# nrf9120_MLM1 register map
Vendor: Nordic Semiconductor; Series: nrf91; File version: 1
CPU: CM4 r0p1, little endian, MPU, FPU, 3 interrupt priority bits
Registers are 32-bit, read-write, reset 0x0 unless marked. A register's access mark holds for its fields unless they carry their own. Offsets are from the block's base; [hi:lo] are bit positions; lines under a group give offsets from that group; {n}, {i} and the like mark numbered series; 'fields as' and 'values as' point back to an identical list.

## SAADC — Analog to Digital Converter
Base 0x4000B000
0x00 TASKS_START wo — Start the ADC and prepare the result buffer in RAM
0x04 TASKS_SAMPLE wo — Take one ADC sample, if scan is enabled all channels are sampled
0x08 TASKS_STOP wo — Stop the ADC and terminate any on-going conversion
0x0C TASKS_CALIBRATEOFFSET wo — Starts offset auto-calibration
0x10 TASKS_CALIBRATEGAIN wo — Starts gain auto-calibration
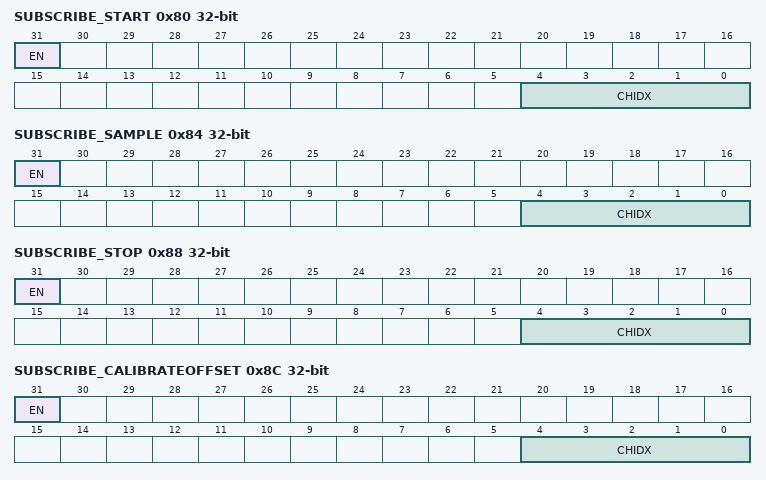
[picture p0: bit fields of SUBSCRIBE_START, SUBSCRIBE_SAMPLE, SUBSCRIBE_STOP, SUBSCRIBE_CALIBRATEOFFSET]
0x80 SUBSCRIBE_START — Subscribe configuration for TASKS_START
  [31] EN
    0=Disabled (Disable subscription); 1=Enabled (Enable subscription)
  [4:0] CHIDX — Channel the TASKS_START will subscribe to.
0x84 SUBSCRIBE_SAMPLE — Subscribe configuration for TASKS_SAMPLE
  [31] EN
    values as SUBSCRIBE_START.EN
  [4:0] CHIDX — Channel the TASKS_SAMPLE will subscribe to.
0x88 SUBSCRIBE_STOP — Subscribe configuration for TASKS_STOP
  [31] EN
    values as SUBSCRIBE_START.EN
  [4:0] CHIDX — Channel the TASKS_STOP will subscribe to.
0x8C SUBSCRIBE_CALIBRATEOFFSET — Subscribe configuration for TASKS_CALIBRATEOFFSET
  [31] EN
    values as SUBSCRIBE_START.EN
  [4:0] CHIDX — Channel the TASKS_CALIBRATEOFFSET will subscribe to.
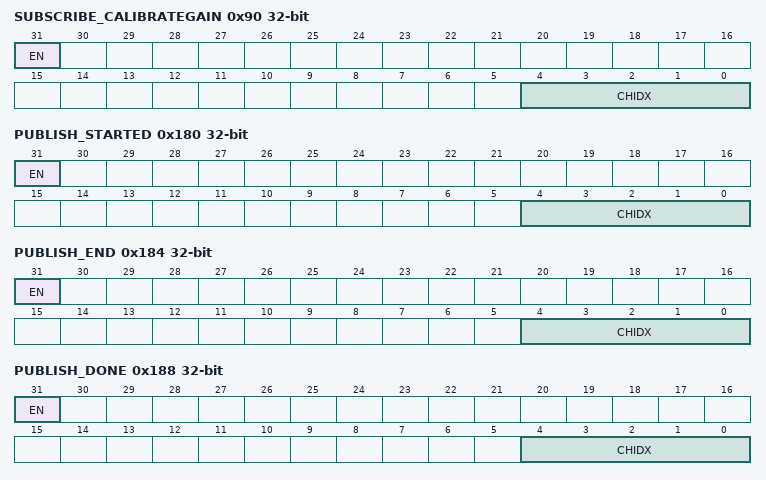
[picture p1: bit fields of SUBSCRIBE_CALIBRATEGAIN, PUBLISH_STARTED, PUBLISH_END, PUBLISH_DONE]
0x90 SUBSCRIBE_CALIBRATEGAIN — Subscribe configuration for TASKS_CALIBRATEGAIN
  [31] EN
    values as SUBSCRIBE_START.EN
  [4:0] CHIDX — Channel the TASKS_CALIBRATEGAIN will subscribe to.
0x100 EVENTS_STARTED — The ADC has started
0x104 EVENTS_END — The ADC has filled up the Result buffer
0x108 EVENTS_DONE — A conversion task has been completed. Depending on the mode, multiple conversions might be needed for a result to be transferred to RAM.
0x10C EVENTS_RESULTDONE — A result is ready to get transferred to RAM. Result is available in REGRESULT register
0x110 EVENTS_CALIBRATEDONE — Calibration is complete
0x114 EVENTS_STOPPED — The ADC has stopped
{0x118+8i} EVENTS_CH[{i}] (i=0..7) group — Unspecified
  0x00 LIMITH — Description cluster[0]: Last results is equal or above CH[0].LIMIT.HIGH
  0x04 LIMITL — Description cluster[0]: Last results is equal or below CH[0].LIMIT.LOW
0x180 PUBLISH_STARTED — Publish configuration for EVENTS_STARTED
  [31] EN
    0=Disabled (Disable publishing); 1=Enabled (Enable publishing)
  [4:0] CHIDX — Channel the EVENTS_STARTED will subscribe to.
0x184 PUBLISH_END — Publish configuration for EVENTS_END
  [31] EN
    values as PUBLISH_STARTED.EN
  [4:0] CHIDX — Channel the EVENTS_END will subscribe to.
0x188 PUBLISH_DONE — Publish configuration for EVENTS_DONE
  [31] EN
    values as PUBLISH_STARTED.EN
  [4:0] CHIDX — Channel the EVENTS_DONE will subscribe to.
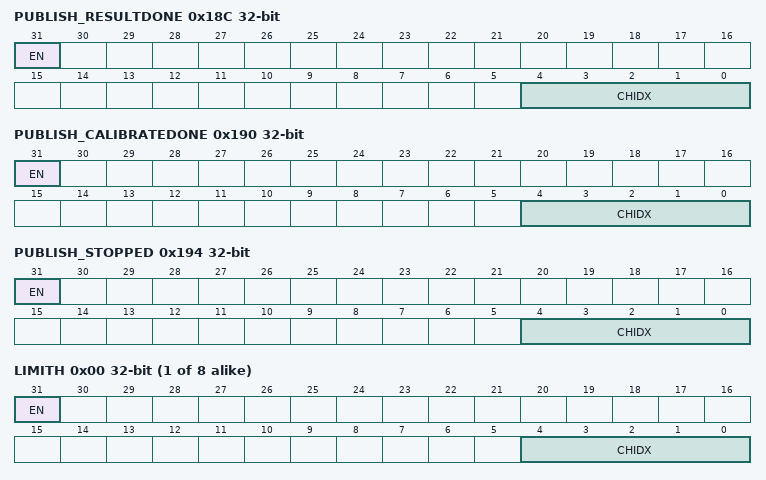
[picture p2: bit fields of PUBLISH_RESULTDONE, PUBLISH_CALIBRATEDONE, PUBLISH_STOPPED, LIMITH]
0x18C PUBLISH_RESULTDONE — Publish configuration for EVENTS_RESULTDONE
  [31] EN
    values as PUBLISH_STARTED.EN
  [4:0] CHIDX — Channel the EVENTS_RESULTDONE will subscribe to.
0x190 PUBLISH_CALIBRATEDONE — Publish configuration for EVENTS_CALIBRATEDONE
  [31] EN
    values as PUBLISH_STARTED.EN
  [4:0] CHIDX — Channel the EVENTS_CALIBRATEDONE will subscribe to.
0x194 PUBLISH_STOPPED — Publish configuration for EVENTS_STOPPED
  [31] EN
    values as PUBLISH_STARTED.EN
  [4:0] CHIDX — Channel the EVENTS_STOPPED will subscribe to.
{0x198+8i} PUBLISH_CH[{i}] (i=0..7) group — Unspecified
  0x00 LIMITH — Description cluster[0]: Publish configuration for EVENTS_CH[0].LIMITH
    [31] EN
      values as PUBLISH_STARTED.EN
    [4:0] CHIDX — Channel the EVENTS_CH[0].LIMITH will subscribe to.
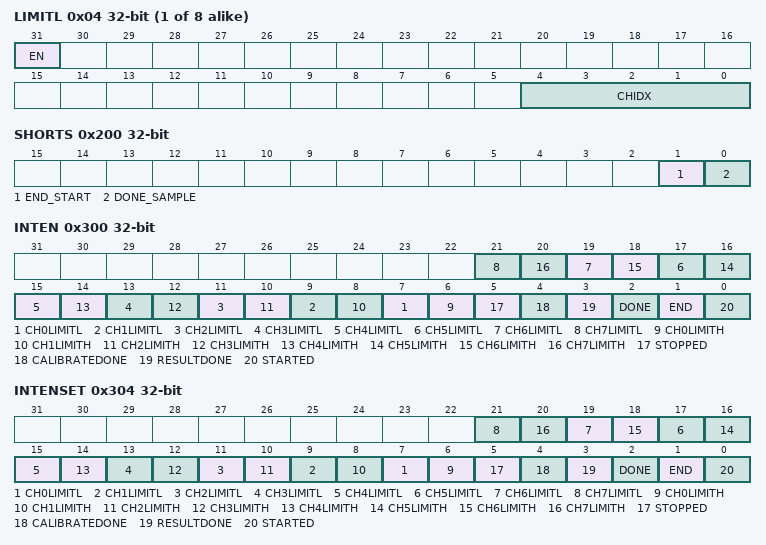
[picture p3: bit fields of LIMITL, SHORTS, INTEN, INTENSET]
  0x04 LIMITL — Description cluster[0]: Publish configuration for EVENTS_CH[0].LIMITL
    [31] EN
      values as PUBLISH_STARTED.EN
    [4:0] CHIDX — Channel the EVENTS_CH[0].LIMITL will subscribe to.
0x200 SHORTS — Shortcut register
  [1] END_START — Shortcut between END event and START task
    0=Disabled (Disable shortcut); 1=Enabled (Enable shortcut)
  [0] DONE_SAMPLE — Shortcut between DONE event and SAMPLE task
    0=Disabled (Disable shortcut); 1=Enabled (Enable shortcut)
0x300 INTEN — Enable or disable interrupt
  [all] fields
    0=Disabled; 1=Enabled
  [2n+7] CH{n}LIMITL (n=0..7) — Enable or disable interrupt for CH[{n}].LIMITL event
  [2n+6] CH{n}LIMITH (n=0..7) — Enable or disable interrupt for CH[{n}].LIMITH event
  [5] STOPPED — Enable or disable interrupt for STOPPED event
  [4] CALIBRATEDONE — Enable or disable interrupt for CALIBRATEDONE event
  [3] RESULTDONE — Enable or disable interrupt for RESULTDONE event
  [2] DONE — Enable or disable interrupt for DONE event
  [1] END — Enable or disable interrupt for END event
  [0] STARTED — Enable or disable interrupt for STARTED event
0x304 INTENSET — Enable interrupt
  [all] fields
    on read: 0=Disabled (Read: Disabled); 1=Enabled (Read: Enabled) | on write: 1=Set (Enable)
  [2n+7] CH{n}LIMITL (n=0..7) — Write '1' to Enable interrupt for CH[{n}].LIMITL event
  [2n+6] CH{n}LIMITH (n=0..7) — Write '1' to Enable interrupt for CH[{n}].LIMITH event
  [5] STOPPED — Write '1' to Enable interrupt for STOPPED event
  [4] CALIBRATEDONE — Write '1' to Enable interrupt for CALIBRATEDONE event
  [3] RESULTDONE — Write '1' to Enable interrupt for RESULTDONE event
  [2] DONE — Write '1' to Enable interrupt for DONE event
  [1] END — Write '1' to Enable interrupt for END event
  [0] STARTED — Write '1' to Enable interrupt for STARTED event
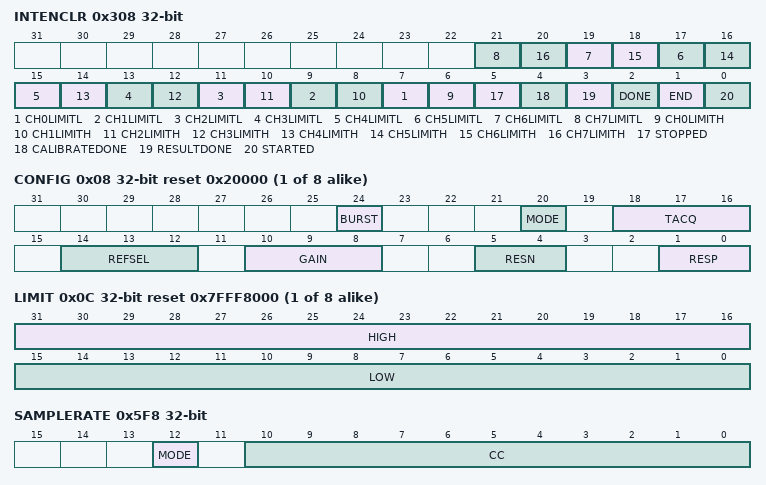
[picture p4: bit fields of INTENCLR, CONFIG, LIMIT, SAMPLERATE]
0x308 INTENCLR — Disable interrupt
  [all] fields
    on read: 0=Disabled (Read: Disabled); 1=Enabled (Read: Enabled) | on write: 1=Clear (Disable)
  [2n+7] CH{n}LIMITL (n=0..7) — Write '1' to Disable interrupt for CH[{n}].LIMITL event
  [2n+6] CH{n}LIMITH (n=0..7) — Write '1' to Disable interrupt for CH[{n}].LIMITH event
  [5] STOPPED — Write '1' to Disable interrupt for STOPPED event
  [4] CALIBRATEDONE — Write '1' to Disable interrupt for CALIBRATEDONE event
  [3] RESULTDONE — Write '1' to Disable interrupt for RESULTDONE event
  [2] DONE — Write '1' to Disable interrupt for DONE event
  [1] END — Write '1' to Disable interrupt for END event
  [0] STARTED — Write '1' to Disable interrupt for STARTED event
0x400 STATUS ro
  [0] STATUS
    0=Ready (ADC is ready. No on-going conversion.); 1=Busy (ADC is busy. Conversion in progress.)
0x500 ENABLE — Enable or disable ADC
  [0] ENABLE
    0=Disabled (Disable ADC); 1=Enabled (Enable ADC)
{0x510+0x10*i} CH[{i}] (i=0..7) group — Unspecified
  0x00 PSELP — Description cluster[0]: Input positive pin selection for CH[0]
    [4:0] PSELP — Analog positive input channel
      0=NC (Not connected); {v}=AnalogInput{v-1} (AIN{v-1}) (v=1..8); 9=VDD; {v}=ATB{v-10} (v=10..13); 14=AVDD1V3; 15=DVDD0V9; 16=SELREF (Selected reference)
  0x04 PSELN — Description cluster[0]: Input negative pin selection for CH[0]
    [4:0] PSELN — Analog negative input, enables differential channel
      values as CH[0].PSELP.PSELP
  0x08 CONFIG reset 0x20000 — Description cluster[0]: Input configuration for CH[0]
    [24] BURST — Enable burst mode
      0=Disabled (Burst mode is disabled (normal operation)); 1=Enabled (Burst mode is enabled. SAADC takes 2^OVERSAMPLE number of samples as fast as it can, and sends the average to Data RAM.)
    [20] MODE — Enable differential mode
      0=SE (Single ended, PSELN will be ignored, negative input to ADC shorted to GND); 1=Differential
    [18:16] TACQ — Acquisition time, the time the ADC uses to sample the input voltage
      0=3us; 1=5us; 2=10us; 3=15us; 4=20us; 5=40us; 6=1us; 7=2us
    [14:12] REFSEL — Reference control
      0=Internal reference (0.6 V); 1=VDD1_4 (VDD/4 as reference); 2=PADCIN1_4 (PADC_IN/4 as reference); 3=ATB0 (ATB0 as reference); 4=ATB1 (ATB1 as reference); 5=MBIAS (MBIAS as reference)
    [10:8] GAIN — Gain control
      0=Gain1_6 (1/6); 1=Gain1_5 (1/5); 2=Gain1_4 (1/4); 3=Gain1_3 (1/3); 4=Gain1_2 (1/2); 5=1; 6=2; 7=4
    [5:4] RESN — Negative channel resistor control
      0=Bypass resistor ladder; 1=Pull-down to GND; 2=Pull-up to VDD; 3=VDD1_2 (Set input at VDD/2)
    [1:0] RESP — Positive channel resistor control
      values as RESN
  0x0C LIMIT reset 0x7FFF8000 — Description cluster[0]: High/low limits for event monitoring a channel
    [31:16] HIGH — High level limit
    [15:0] LOW — Low level limit
0x5EC REGRESULT ro — Last conversion result
  [31:0] REGRESULT — Result of the previous ADC conversion
0x5F0 RESOLUTION reset 0x1 — Resolution configuration
  [2:0] VAL — Set the resolution
    0=8bit; 1=10bit; 2=12bit; 3=14bit; 4=16bit
0x5F4 OVERSAMPLE — Oversampling configuration. OVERSAMPLE should not be combined with SCAN. The RESOLUTION is applied before averaging, thus for high OVERSAMPLE a higher RESOLUTION should be used.
  [3:0] OVERSAMPLE — Oversample control
    0=Bypass oversampling; 1=Over2x (Oversample 2x); 2=Over4x (Oversample 4x); 3=Over8x (Oversample 8x); 4=Over16x (Oversample 16x); 5=Over32x (Oversample 32x); 6=Over64x (Oversample 64x); 7=Over128x (Oversample 128x); 8=Over256x (Oversample 256x); 9=Over512x (Oversample 512x); 10=Over1024x (Oversample 1024x); 11=Over2048x (Oversample 2048x); 12=Over4096x (Oversample 4096x)
0x5F8 SAMPLERATE — Controls normal or continuous sample rate
  [12] MODE — Select mode for sample rate control
    0=Task (Rate is controlled from SAMPLE task); 1=Timers (Rate is controlled from local timer (use CC to control the rate))
  [10:0] CC — Capture and compare value. Sample rate is 16 MHz/CC
0x62C RESULT group — RESULT EasyDMA channel
  0x00 PTR — Data pointer
  0x04 MAXCNT — Maximum number of buffer words to transfer
    [14:0] MAXCNT
  0x08 AMOUNT ro — Number of buffer words transferred since last START
    [14:0] AMOUNT — Number of buffer words transferred since last START. This register can be read after an END or STOPPED event.
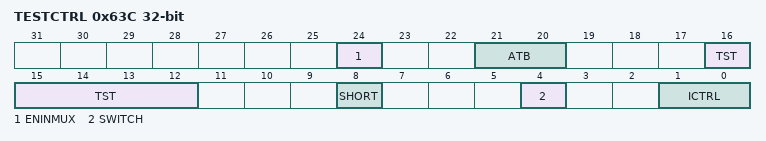
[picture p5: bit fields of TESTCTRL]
0x63C TESTCTRL — Control signals used during test of ADC
  [24] ENINMUX — Will enable the input mux in the ADC, so the resistor strings can be connected even when the analog core is powered down
  [21:20] ATB — Analog testbus control
    0=Disabled (ATB disabled); 1=VREF (Internal reference on ATB0, buffered reference on ATB1)
  [16:12] TST — Test bus for ADC core, see design description for coding
  [8] SHORT — Short input. Used to measure offset of ADC.
  [4] SWITCH — Swap positive and negative input
  [1:0] ICTRL — Current control, 0 = normal current, higher is higher current
0x640 CALOFFSET — Calibration control for offset error
  [5:0] CALOFFSET — Sign-magnitude coding
0x644 CALGAIN reset 0x40 — Calibration control for gain error
  [6:0] CALGAIN — Offset binary coding
0x648 CALVREF reset 0x40 — Calibration control for reference voltage
  [6:0] CALVREF — Offset binary coding
0xFFC POWER reset 0x1 — Peripheral power control
  [0] POWER — Peripheral power control. The peripheral and its registers will be reset to its initial state by switching the peripheral off and then back on again.
    0=Disabled (Peripheral is powered off); 1=Enabled (Peripheral is powered on)
